# MAIN_SEC_MMR_MAIN_SEC_MMR_CFG0_45A00000h register map
Vendor: Texas Instruments
Peripheral module from a debugger description file (folder am62L).
Registers are 32-bit, read-only, reset 0x0 unless marked. A register's access mark holds for its fields unless they carry their own. Offsets are as the file gives them; lines under a group give offsets from that group; [hi:lo] are bit positions; {n}, {i} and the like mark numbered series; 'fields as' and 'values as' point back to an identical list; <NAME> marks a mode.

## MAIN_SEC_MMR_CFG0
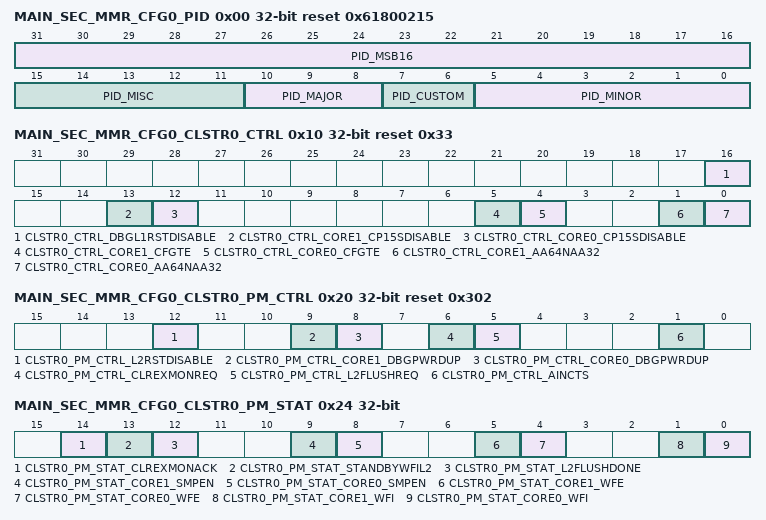
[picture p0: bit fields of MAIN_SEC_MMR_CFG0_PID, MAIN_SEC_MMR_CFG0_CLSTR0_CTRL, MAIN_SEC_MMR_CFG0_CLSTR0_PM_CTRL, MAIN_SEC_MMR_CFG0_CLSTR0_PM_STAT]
0x00 MAIN_SEC_MMR_CFG0_PID reset 0x61800215
  [31:16] PID_MSB16 — Reset Source: mod_g_rst_n
  [15:11] PID_MISC — Reset Source: mod_g_rst_n
  [10:8] PID_MAJOR — Reset Source: mod_g_rst_n
  [7:6] PID_CUSTOM — Reset Source: mod_g_rst_n
  [5:0] PID_MINOR — Reset Source: mod_g_rst_n
0x10 MAIN_SEC_MMR_CFG0_CLSTR0_CTRL access per field reset 0x33 — Configures Cluster0
  [16] CLSTR0_CTRL_DBGL1RSTDISABLE rw — Deactivate L1 data cache automatic invalidate on reset functionality.This bit must not be set during normal operation. It may only be set when debugging an external watchdog reset, and analysis of the contents of L1 is necessary for debug purposes.This bit is only sampled by the processor at reset. Field values (others are reserved):1'b0 - Enable automatic invalidation of L1 data cache on reset1'b1 - Disable automatic invalidation of L1 data cache on reset Reset Source: sys_por_rst_n
  [13] CLSTR0_CTRL_CORE1_CP15SDISABLE rw — Controls Core access to Coprocessor 15 by Cluster0 Core1 Reset Source: sys_por_rst_n
  [12] CLSTR0_CTRL_CORE0_CP15SDISABLE rw — Controls Core access to Coprocessor 15 by Cluster0 Core0 Reset Source: sys_por_rst_n
  [5] CLSTR0_CTRL_CORE1_CFGTE ro — Core1 ARM Exception Mode configuration at Reset. Permanently set to Thumb2. Reset Source: sys_por_rst_n
  [4] CLSTR0_CTRL_CORE0_CFGTE ro — Core0 ARM Exception Mode configuration at Reset. Permanently set to Thumb2. Reset Source: sys_por_rst_n
  [1] CLSTR0_CTRL_CORE1_AA64NAA32 ro — Core1 ARM Architecture configuration at Reset. Permanently set to AArch64. Reset Source: sys_por_rst_n
  [0] CLSTR0_CTRL_CORE0_AA64NAA32 ro — Core0 ARM Architecture configuration at Reset. Permanently set to AArch64. Reset Source: sys_por_rst_n
0x18 MAIN_SEC_MMR_CFG0_CLSTR0_STAT — Status of Cluster0
  [31:0] CLSTR0_STAT_RSV — reserved Reset Source: sys_por_rst_n
0x20 MAIN_SEC_MMR_CFG0_CLSTR0_PM_CTRL rw reset 0x302 — Power Management Control of Cluster0
  [12] CLSTR0_PM_CTRL_L2RSTDISABLE — Deactivate L2 cache automatic invalidate on reset functionality.This bit is only sampled by the processor at reset. Reset Source: sys_por_rst_n
  [9] CLSTR0_PM_CTRL_CORE1_DBGPWRDUP — Core1 powered up0 - Core is powered down1 - Core is powered up Reset Source: sys_por_rst_n
  [8] CLSTR0_PM_CTRL_CORE0_DBGPWRDUP — Core0 powered up0 - Core is powered down1 - Core is powered up Reset Source: sys_por_rst_n
  [6] CLSTR0_PM_CTRL_CLREXMONREQ — Request to clear the external global exclusive monitor.This sends a WFE wake-up event to all cores in the cluster. When set HIGH the global exclusive monitor in the system is requesting the processor EVENT registers to be set HIGH. Reset Source: sys_por_rst_n
  [5] CLSTR0_PM_CTRL_L2FLUSHREQ — L2 hardware flush request. Reset Source: sys_por_rst_n
  [1] CLSTR0_PM_CTRL_AINCTS — The SOC asserts this bit to indicate that no more transactions are being sent to the ACP interface, and that the ACP Interface Should Idle. This is asserted by the SOC as part of the low power mode entry sequence. Reset Source: sys_por_rst_n
0x24 MAIN_SEC_MMR_CFG0_CLSTR0_PM_STAT — Power Management Status of Cluster0
  [14] CLSTR0_PM_STAT_CLREXMONACK — External global exclusive monitor clear acknowledge.Set HIGH to acknowledge the receipt of the CLREXMONREQ input (PM_CONFIG0_clear_mon0 is set). Indicates that the processor EVENT registers have been set HIGH. Reset Source: mod_g_rst_n
  [13] CLSTR0_PM_STAT_STANDBYWFIL2 — Indicates L2 low power state0 - L2 not in low power state1 - L2 is in WFI low power state Reset Source: mod_g_rst_n
  [12] CLSTR0_PM_STAT_L2FLUSHDONE — L2 hardware flush complete Reset Source: mod_g_rst_n
  [9] CLSTR0_PM_STAT_CORE1_SMPEN — Core1 coherency indicator0 - Core is taking part in coherency1 - Core is not taking part in coherency Reset Source: mod_g_rst_n
  [8] CLSTR0_PM_STAT_CORE0_SMPEN — Core0 coherency indicator0 - Core is taking part in coherency1 - Core is not taking part in coherency Reset Source: mod_g_rst_n
  [5] CLSTR0_PM_STAT_CORE1_WFE — Indicates Core1 in WFE stateNote: Informaton is only valid when core is out of reset. Reset Source: mod_g_rst_n
  [4] CLSTR0_PM_STAT_CORE0_WFE — Indicates Core0 in WFE stateNote: Informaton is only valid when core is out of reset. Reset Source: mod_g_rst_n
  [1] CLSTR0_PM_STAT_CORE1_WFI — Indicates Core1 in WFI stateNote: Informaton is only valid when core is out of reset. Reset Source: mod_g_rst_n
  [0] CLSTR0_PM_STAT_CORE0_WFI — Indicates Core0 in WFI stateNote: Informaton is only valid when core is out of reset. Reset Source: mod_g_rst_n
0x100 MAIN_SEC_MMR_CFG0_CLSTR0_CORE0_CTRL — Configures Core0 of Cluster0
  [31:0] CLSTR0_CORE0_CTRL_RSV — reserved Reset Source: sys_por_rst_n
0x104 MAIN_SEC_MMR_CFG0_CLSTR0_CORE0_STAT — Status of Core0 of Cluster0
  [31:0] CLSTR0_CORE0_STAT_RSV — reserved Reset Source: sys_por_rst_n
0x10C MAIN_SEC_MMR_CFG0_CLSTR0_CORE0_BOOTVECT rw — Boot Vector for Core0 of Cluster0
  [31:0] CLSTR0_CORE0_BOOTVECT_VECT_ADDR — The reset vector for Cluster0, Cluster0 Core0. Address bits [35:4] of the 36 bit reset vector address of the CPU. Bits[3:0] are not programmable (tied 4'b0000) Reset Source: sys_por_rst_n
0x110 MAIN_SEC_MMR_CFG0_CLSTR0_CORE1_CTRL — Configures Core1 of Cluster0
  [31:0] CLSTR0_CORE1_CTRL_RSV — reserved Reset Source: sys_por_rst_n
0x114 MAIN_SEC_MMR_CFG0_CLSTR0_CORE1_STAT — Status of Core1 of Cluster0
  [31:0] CLSTR0_CORE1_STAT_RSV — reserved Reset Source: sys_por_rst_n
0x11C MAIN_SEC_MMR_CFG0_CLSTR0_CORE1_BOOTVECT rw — Boot Vector for Core1 of Cluster0
  [31:0] CLSTR0_CORE1_BOOTVECT_VECT_ADDR — The reset vector for Cluster0, Cluster0 Core1. Address bits [35:4] of the 36 bit reset vector address of the CPU. Bits[3:0] are not programmable (tied 4'b0000) Reset Source: sys_por_rst_n
